# MKL28T7_CORE1 register map
Vendor: Freescale Semiconductor, Inc.; Series: Kinetis_L; File version: 1.6
CPU: CM0PLUS r0p0, little endian, no MPU, no FPU, VTOR, 2 interrupt priority bits
Registers are 32-bit, read-write, reset 0x0 unless marked. A register's access mark holds for its fields unless they carry their own. Offsets are from the block's base; [hi:lo] are bit positions; {n}, {i} and the like mark numbered series; 'fields as' and 'values as' point back to an identical list.

## LLWU0 — Low leakage wakeup unit
Base 0x40061000; register names take the prefix LLWU0_
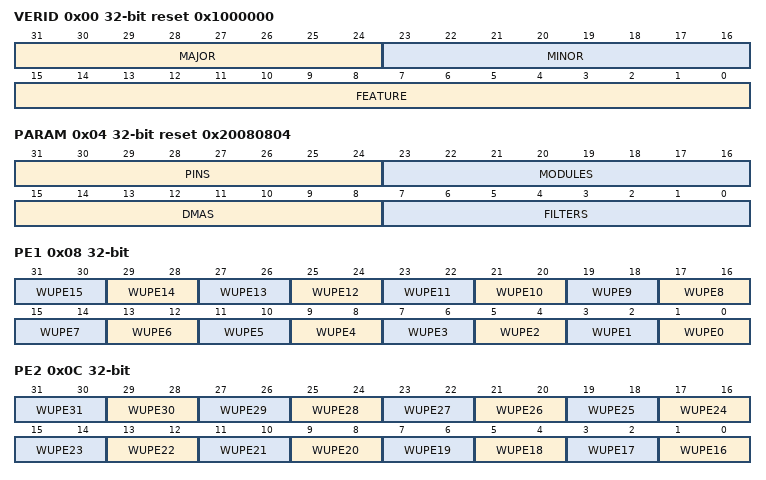
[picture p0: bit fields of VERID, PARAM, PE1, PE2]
0x00 VERID ro reset 0x1000000 — Version ID Register
  [31:24] MAJOR — Major Version Number
  [23:16] MINOR — Minor Version Number
  [15:0] FEATURE — Feature Specification Number
    0=Standard features implemented
0x04 PARAM ro reset 0x20080804 — Parameter Register
  [31:24] PINS — Pin Number
  [23:16] MODULES — Module Number
  [15:8] DMAS — DMA Number
  [7:0] FILTERS — Filter Number
0x08 PE1 — LLWU Pin Enable 1 register
  [all] fields
    0=External input pin disabled as wakeup input; 1=External input pin enabled with rising edge detection; 2=External input pin enabled with falling edge detection; 3=External input pin enabled with any change detection
  [2n+1:2n] WUPE{n} (n=0..15) — Wakeup Pin Enable For LLWU_P{n}
0x0C PE2 — LLWU Pin Enable 2 register
  [all] fields
    values as the fields of PE1
  [2n-31:2n-32] WUPE{n} (n=16..31) — Wakeup Pin Enable For LLWU_P{n}
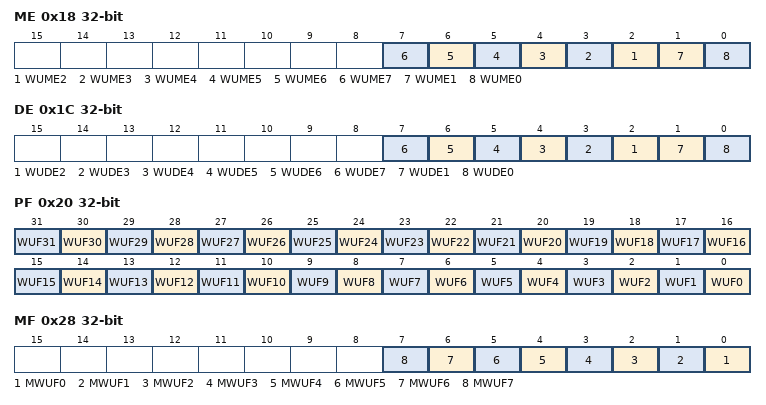
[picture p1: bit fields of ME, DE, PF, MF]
0x18 ME — LLWU Module Interrupt Enable register
  [all] fields
    0=Internal module flag not used as wakeup source; 1=Internal module flag used as wakeup source
  [n] WUME{n} (n=2..7) — Wakeup Module Enable For Module {n}
  [1] WUME1 — Wakeup Module Enable for Module 1
  [0] WUME0 — Wakeup Module Enable For Module 0
0x1C DE — LLWU Module DMA Enable register
  [all] fields
    0=Internal module request not used as a DMA wakeup source; 1=Internal module request used as a DMA wakeup source
  [n] WUDE{n} (n=2..7) — DMA Wakeup Enable For Module {n}
  [1] WUDE1 — DMA Wakeup Enable for Module 1
  [0] WUDE0 — DMA Wakeup Enable For Module 0
0x20 PF — LLWU Pin Flag register
  [n] WUF{n} (n=0..31) — Wakeup Flag For LLWU_P{n}
    0=LLWU_P{n} input was not a wakeup source; 1=LLWU_P{n} input was a wakeup source
0x28 MF ro — LLWU Module Interrupt Flag register
  [n] MWUF{n} (n=0..7) — Wakeup flag For module {n}
    0=Module {n} input was not a wakeup source; 1=Module {n} input was a wakeup source
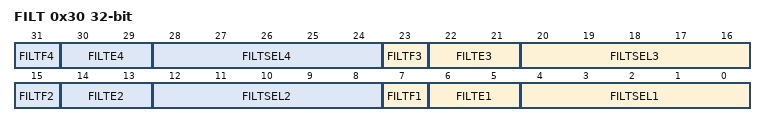
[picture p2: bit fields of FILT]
0x30 FILT — LLWU Pin Filter register
  [8n-1] FILTF{n} (n=1..4) — Filter {n} Flag
    0=Pin Filter 1 was not a wakeup source; 1=Pin Filter 1 was a wakeup source
  [8n-2:8n-3] FILTE{n} (n=1..4) — Filter {n} Enable
    0=Filter disabled; 1=Filter posedge detect enabled; 2=Filter negedge detect enabled; 3=Filter any edge detect enabled
  [8n-4:8n-8] FILTSEL{n} (n=1..4) — Filter {n} Pin Select
    0=Select LLWU_P0 for filter; 31=Select LLWU_P31 for filter

## LLWU1 — Low leakage wakeup unit
Base 0x400E1000; register names take the prefix LLWU1_
Registers as LLWU0.

## TSI0 — Touch sense input
Base 0x40062000; register names take the prefix TSI0_
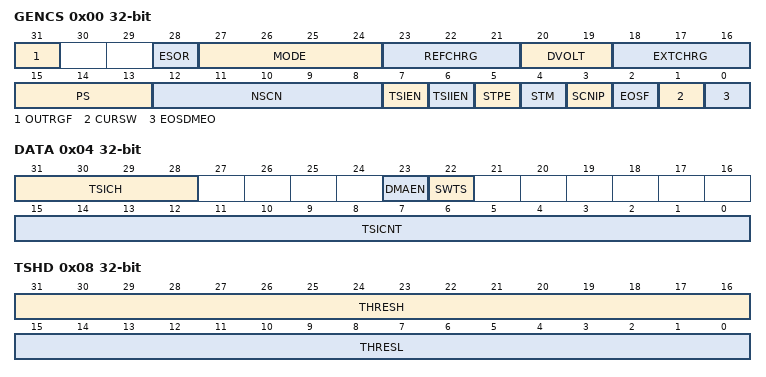
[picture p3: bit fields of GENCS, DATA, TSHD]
0x00 GENCS — TSI General Control and Status Register
  [31] OUTRGF — Out of Range Flag.
  [28] ESOR — End-of-scan or Out-of-Range Interrupt Selection
    0=Out-of-range interrupt is allowed; 1=End-of-scan interrupt is allowed
  [27:24] MODE — TSI analog modes setup and status bits.
    0=Set TSI in capacitive sensing(non-noise detection) mode; 4=Set TSI analog to work in single threshold noise detection mode and the frequency limitation circuit is disabled; 8=Set TSI analog to work in single threshold noise detection mode and the frequency limitation circuit is enabled to work in higher frequencies operations; 12=Set TSI analog to work in automatic noise detection mode
  [23:21] REFCHRG
    0=500 nA; 1=1 uA; 2=2 uA; 3=4 uA; 4=8 uA; 5=16 uA; 6=32 uA; 7=64 uA
  [20:19] DVOLT
    0=DV = 1.026 V; VP = 1.328 V; Vm = 0.302 V; 1=DV = 0.592 V; VP = 1.111 V; Vm = 0.519 V; 2=DV = 0.342 V; VP = 0.986 V; Vm = 0.644 V; 3=DV = 0.197 V; VP = 0.914 V; Vm = 0.716 V
  [18:16] EXTCHRG
    values as REFCHRG
  [15:13] PS
    0=Electrode Oscillator Frequency divided by 1; 1=Electrode Oscillator Frequency divided by 2; 2=Electrode Oscillator Frequency divided by 4; 3=Electrode Oscillator Frequency divided by 8; 4=Electrode Oscillator Frequency divided by 16; 5=Electrode Oscillator Frequency divided by 32; 6=Electrode Oscillator Frequency divided by 64; 7=Electrode Oscillator Frequency divided by 128
  [12:8] NSCN
    0=Once per electrode; 1=Twice per electrode; {v}={v+1} times per electrode (v=2..31)
  [7] TSIEN — Touch Sensing Input Module Enable
    0=TSI module disabled; 1=TSI module enabled
  [6] TSIIEN — Touch Sensing Input Interrupt Enable
    0=TSI interrupt is disabled; 1=TSI interrupt is enabled
  [5] STPE — TSI STOP Enable
    0=TSI is disabled when MCU goes into low power mode; 1=Allows TSI to continue running in all low power modes
  [4] STM — Scan Trigger Mode
    0=Software trigger scan; 1=Hardware trigger scan
  [3] SCNIP ro — Scan In Progress Status
    0=No scan in progress; 1=Scan in progress
  [2] EOSF — End of Scan Flag
    0=Scan not complete; 1=Scan complete
  [1] CURSW
    0=The current source pair are not swapped; 1=The current source pair are swapped
  [0] EOSDMEO — End-of-Scan DMA Transfer Request Enable Only
    0=Do not enable the End-of-Scan DMA transfer request only. Depending on ESOR state, either Out-of-Range or End-of-Scan can trigger a DMA transfer request and interrupt.; 1=Only the End-of-Scan event can trigger a DMA transfer request. The Out-of-Range event only and always triggers an interrupt if TSIIE is set.
0x04 DATA — TSI DATA Register
  [31:28] TSICH
    {v}=Channel {v} (v=0..15)
  [23] DMAEN — DMA Transfer Enabled
    0=Interrupt is selected when the interrupt enable bit is set and the corresponding TSI events assert; 1=DMA transfer request is selected when the interrupt enable bit is set and the corresponding TSI events assert
  [22] SWTS wo — Software Trigger Start
    0=No effect; 1=Start a scan to determine which channel is specified by TSI_DATA[TSICH]
  [15:0] TSICNT ro — TSI Conversion Counter Value
0x08 TSHD — TSI Threshold Register
  [31:16] THRESH — TSI Wakeup Channel High-threshold
  [15:0] THRESL — TSI Wakeup Channel Low-threshold
